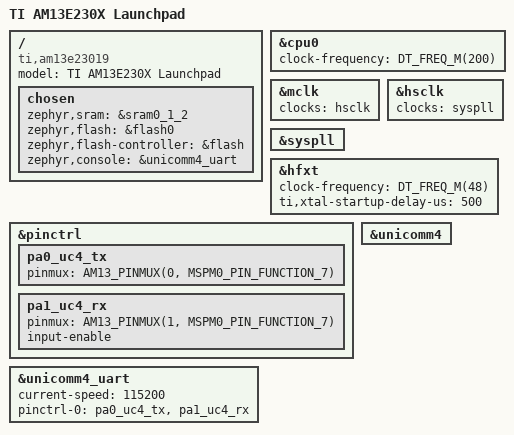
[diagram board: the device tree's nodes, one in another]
/*
 * Copyright (c) 2026 Texas Instruments Incorporated
 *
 * SPDX-License-Identifier: Apache-2.0
 */

/dts-v1/;

#include <ti/am13/am13e23019.dtsi>
#include <zephyr/dt-bindings/pinctrl/am13-pinctrl.h>

/ {
	model = "TI AM13E230X Launchpad";
	compatible = "ti,am13e23019";

	chosen {
		zephyr,sram = &sram0_1_2;
		zephyr,flash = &flash0;
		zephyr,flash-controller = &flash;
		zephyr,console = &unicomm4_uart;
	};
};

&cpu0 {
	clock-frequency = <DT_FREQ_M(200)>;
};

&mclk {
	clocks = <&hsclk>;
};

&hsclk {
	clocks = <&syspll>;
	status = "okay";
};

&syspll {
	status = "okay";
};

&hfxt {
	clock-frequency = <DT_FREQ_M(48)>;
	ti,xtal-startup-delay-us = <500>;
};

&pinctrl {
	pa0_uc4_tx: pa0_uc4_tx {
		pinmux = <AM13_PINMUX(0, MSPM0_PIN_FUNCTION_7)>;
	};

	pa1_uc4_rx: pa1_uc4_rx {
		pinmux = <AM13_PINMUX(1, MSPM0_PIN_FUNCTION_7)>;
		input-enable;
	};
};

&unicomm4 {
	status = "okay";
};

&unicomm4_uart {
	status = "okay";
	current-speed = <115200>;

	pinctrl-0 = <&pa0_uc4_tx &pa1_uc4_rx>;
	pinctrl-names = "default";
};
